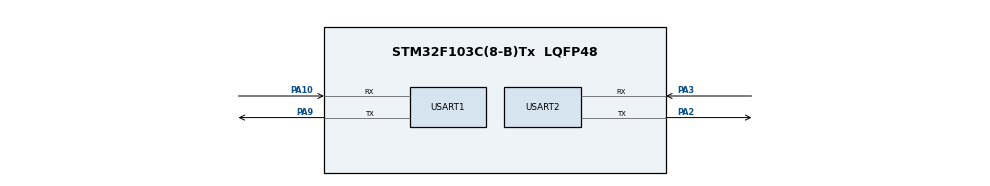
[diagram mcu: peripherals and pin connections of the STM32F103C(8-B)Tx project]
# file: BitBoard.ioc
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FREERTOS.Tasks01=defaultTask,0,128,StartDefaultTask,Default
Mcu.Family=STM32F1
Mcu.Name=STM32F103C(8-B)Tx
Mcu.Package=LQFP48
NVIC.PriorityGroup=NVIC_PRIORITYGROUP_4
PA10.Mode=Multiprocessor_communication
PA10.Signal=USART1_RX
PA2.Mode=Multiprocessor_communication
PA2.Signal=USART2_TX
PA3.Mode=Multiprocessor_communication
PA3.Signal=USART2_RX
PA9.Mode=Multiprocessor_communication
PA9.Signal=USART1_TX
ProjectManager.HeapSize=0x200
ProjectManager.StackSize=0x400
ProjectManager.TargetToolchain=SW4STM32
RCC.APB1Freq_Value=8000000
RCC.APB2Freq_Value=8000000
VP_CRC_VS_CRC.Mode=CRC_Activate
VP_FREERTOS_VS_ENABLE.Mode=Enabled
VP_IWDG_VS_IWDG.Mode=IWDG_Activate
VP_RTC_No_RTC_Output.Mode=RTC_OUT_NO
VP_SYS_VS_ND.Mode=No_Debug
board=BitBoard

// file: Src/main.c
/**
  ******************************************************************************
  * File Name          : main.c
  * Description        : Main program body
  ******************************************************************************
  *
  * COPYRIGHT(c) 2016 STMicroelectronics
  *
  * Redistribution and use in source and binary forms, with or without modification,
  * are permitted provided that the following conditions are met:
  *   1. Redistributions of source code must retain the above copyright notice,
  *      this list of conditions and the following disclaimer.
  *   2. Redistributions in binary form must reproduce the above copyright notice,
  *      this list of conditions and the following disclaimer in the documentation
  *      and/or other materials provided with the distribution.
  *   3. Neither the name of STMicroelectronics nor the names of its contributors
  *      may be used to endorse or promote products derived from this software
  *      without specific prior written permission.
  *
  * THIS SOFTWARE IS PROVIDED BY THE COPYRIGHT HOLDERS AND CONTRIBUTORS "AS IS"
  * AND ANY EXPRESS OR IMPLIED WARRANTIES, INCLUDING, BUT NOT LIMITED TO, THE
  * IMPLIED WARRANTIES OF MERCHANTABILITY AND FITNESS FOR A PARTICULAR PURPOSE ARE
  * DISCLAIMED. IN NO EVENT SHALL THE COPYRIGHT HOLDER OR CONTRIBUTORS BE LIABLE
  * FOR ANY DIRECT, INDIRECT, INCIDENTAL, SPECIAL, EXEMPLARY, OR CONSEQUENTIAL
  * DAMAGES (INCLUDING, BUT NOT LIMITED TO, PROCUREMENT OF SUBSTITUTE GOODS OR
  * SERVICES; LOSS OF USE, DATA, OR PROFITS; OR BUSINESS INTERRUPTION) HOWEVER
  * CAUSED AND ON ANY THEORY OF LIABILITY, WHETHER IN CONTRACT, STRICT LIABILITY,
  * OR TORT (INCLUDING NEGLIGENCE OR OTHERWISE) ARISING IN ANY WAY OUT OF THE USE
  * OF THIS SOFTWARE, EVEN IF ADVISED OF THE POSSIBILITY OF SUCH DAMAGE.
  *
  ******************************************************************************
  */
#include "stm32f1xx_hal.h"
#include "cmsis_os.h"

CRC_HandleTypeDef hcrc;

IWDG_HandleTypeDef hiwdg;

RTC_HandleTypeDef hrtc;

UART_HandleTypeDef huart1;
UART_HandleTypeDef huart2;

osThreadId defaultTaskHandle;

/* USER CODE BEGIN PV */
/* Private variables ---------------------------------------------------------*/

/* USER CODE END PV */

void SystemClock_Config(void);
void Error_Handler(void);
static void MX_GPIO_Init(void);
static void MX_CRC_Init(void);
static void MX_IWDG_Init(void);
static void MX_RTC_Init(void);
static void MX_USART1_UART_Init(void);
static void MX_USART2_UART_Init(void);
void StartDefaultTask(void const * argument);

/* USER CODE BEGIN PFP */
/* Private function prototypes -----------------------------------------------*/

/* USER CODE END PFP */

int main(void)
{

  /* MCU Configuration----------------------------------------------------------*/

  /* Reset of all peripherals, Initializes the Flash interface and the Systick. */
  HAL_Init();

  /* Configure the system clock */
  SystemClock_Config();

  /* Initialize all configured peripherals */
  MX_GPIO_Init();
  MX_CRC_Init();
  MX_IWDG_Init();
  MX_RTC_Init();
  MX_USART1_UART_Init();
  MX_USART2_UART_Init();

  /* Create the thread(s) */
  /* definition and creation of defaultTask */
  osThreadDef(defaultTask, StartDefaultTask, osPriorityNormal, 0, 128);
  defaultTaskHandle = osThreadCreate(osThread(defaultTask), NULL);

  /* Start scheduler */
  osKernelStart();

  /* We should never get here as control is now taken by the scheduler */

  /* Infinite loop */
  /* USER CODE BEGIN WHILE */
  while (1)
  {
	  char loop_str[] = "main loop \n";
  /* USER CODE END WHILE */
	  HAL_UART_Transmit_IT(USART1, loop_str, strlen(loop_str));
  }

}

/** System Clock Configuration
*/
void SystemClock_Config(void)
{

  RCC_OscInitTypeDef RCC_OscInitStruct;
  RCC_ClkInitTypeDef RCC_ClkInitStruct;
  RCC_PeriphCLKInitTypeDef PeriphClkInit;

  RCC_OscInitStruct.OscillatorType = RCC_OSCILLATORTYPE_HSI|RCC_OSCILLATORTYPE_LSI;
  RCC_OscInitStruct.HSIState = RCC_HSI_ON;
  RCC_OscInitStruct.HSICalibrationValue = 16;
  RCC_OscInitStruct.LSIState = RCC_LSI_ON;
  RCC_OscInitStruct.PLL.PLLState = RCC_PLL_NONE;
  if (HAL_RCC_OscConfig(&RCC_OscInitStruct) != HAL_OK)
  {
    Error_Handler();
  }

  RCC_ClkInitStruct.ClockType = RCC_CLOCKTYPE_HCLK|RCC_CLOCKTYPE_SYSCLK
                              |RCC_CLOCKTYPE_PCLK1|RCC_CLOCKTYPE_PCLK2;
  RCC_ClkInitStruct.SYSCLKSource = RCC_SYSCLKSOURCE_HSI;
  RCC_ClkInitStruct.AHBCLKDivider = RCC_SYSCLK_DIV1;
  RCC_ClkInitStruct.APB1CLKDivider = RCC_HCLK_DIV1;
  RCC_ClkInitStruct.APB2CLKDivider = RCC_HCLK_DIV1;
  if (HAL_RCC_ClockConfig(&RCC_ClkInitStruct, FLASH_LATENCY_0) != HAL_OK)
  {
    Error_Handler();
  }

  PeriphClkInit.PeriphClockSelection = RCC_PERIPHCLK_RTC;
  PeriphClkInit.RTCClockSelection = RCC_RTCCLKSOURCE_LSI;
  if (HAL_RCCEx_PeriphCLKConfig(&PeriphClkInit) != HAL_OK)
  {
    Error_Handler();
  }

  HAL_SYSTICK_Config(HAL_RCC_GetHCLKFreq()/1000);

  HAL_SYSTICK_CLKSourceConfig(SYSTICK_CLKSOURCE_HCLK);

  /* SysTick_IRQn interrupt configuration */
  HAL_NVIC_SetPriority(SysTick_IRQn, 15, 0);
}

/* CRC init function */
static void MX_CRC_Init(void)
{

  hcrc.Instance = CRC;
  if (HAL_CRC_Init(&hcrc) != HAL_OK)
  {
    Error_Handler();
  }

}

/* IWDG init function */
static void MX_IWDG_Init(void)
{

  hiwdg.Instance = IWDG;
  hiwdg.Init.Prescaler = IWDG_PRESCALER_4;
  hiwdg.Init.Reload = 4095;
  if (HAL_IWDG_Init(&hiwdg) != HAL_OK)
  {
    Error_Handler();
  }

}

/* RTC init function */
static void MX_RTC_Init(void)
{

  RTC_TimeTypeDef sTime;
  RTC_DateTypeDef DateToUpdate;

    /**Initialize RTC and set the Time and Date
    */
  hrtc.Instance = RTC;
  hrtc.Init.AsynchPrediv = RTC_AUTO_1_SECOND;
  hrtc.Init.OutPut = RTC_OUTPUTSOURCE_NONE;
  if (HAL_RTC_Init(&hrtc) != HAL_OK)
  {
    Error_Handler();
  }

  sTime.Hours = 0x1;
  sTime.Minutes = 0x0;
  sTime.Seconds = 0x0;

  if (HAL_RTC_SetTime(&hrtc, &sTime, RTC_FORMAT_BCD) != HAL_OK)
  {
    Error_Handler();
  }

  DateToUpdate.WeekDay = RTC_WEEKDAY_MONDAY;
  DateToUpdate.Month = RTC_MONTH_JANUARY;
  DateToUpdate.Date = 0x1;
  DateToUpdate.Year = 0x0;

  if (HAL_RTC_SetDate(&hrtc, &DateToUpdate, RTC_FORMAT_BCD) != HAL_OK)
  {
    Error_Handler();
  }

}

/* USART1 init function */
static void MX_USART1_UART_Init(void)
{

  huart1.Instance = USART1;
  huart1.Init.BaudRate = 115200;
  huart1.Init.WordLength = UART_WORDLENGTH_8B;
  huart1.Init.StopBits = UART_STOPBITS_1;
  huart1.Init.Parity = UART_PARITY_NONE;
  huart1.Init.Mode = UART_MODE_TX_RX;
  huart1.Init.HwFlowCtl = UART_HWCONTROL_NONE;
  huart1.Init.OverSampling = UART_OVERSAMPLING_16;
  if (HAL_MultiProcessor_Init(&huart1, 0, UART_WAKEUPMETHOD_IDLELINE) != HAL_OK)
  {
    Error_Handler();
  }

}

/* USART2 init function */
static void MX_USART2_UART_Init(void)
{

  huart2.Instance = USART2;
  huart2.Init.BaudRate = 115200;
  huart2.Init.WordLength = UART_WORDLENGTH_8B;
  huart2.Init.StopBits = UART_STOPBITS_1;
  huart2.Init.Parity = UART_PARITY_NONE;
  huart2.Init.Mode = UART_MODE_TX_RX;
  huart2.Init.HwFlowCtl = UART_HWCONTROL_NONE;
  huart2.Init.OverSampling = UART_OVERSAMPLING_16;
  if (HAL_MultiProcessor_Init(&huart2, 0, UART_WAKEUPMETHOD_IDLELINE) != HAL_OK)
  {
    Error_Handler();
  }

}

/** Pinout Configuration
*/
static void MX_GPIO_Init(void)
{

  /* GPIO Ports Clock Enable */
  __HAL_RCC_GPIOA_CLK_ENABLE();

}

/* StartDefaultTask function */
void StartDefaultTask(void const * argument)
{

  /* USER CODE BEGIN 5 */
  /* Infinite loop */
  for(;;)
  {
	  char loop_str[] = "main loop \n";
  /* USER CODE END WHILE */
      HAL_UART_Transmit_IT(&huart1, loop_str, strlen(loop_str));
  /* USER CODE BEGIN 3 */
    osDelay(1);
  }
  /* USER CODE END 5 */
}

void Error_Handler(void)
{
  while(1)
  {
  }
}

/************************ (C) COPYRIGHT STMicroelectronics *****END OF FILE****/
